# PRM_WKUP register map
Vendor: Texas Instruments
Peripheral module from a debugger description file (folder am335x).
Registers are 32-bit, access per field, no defined reset value unless marked. A register's access mark holds for its fields unless they carry their own. Offsets are as the file gives them; lines under a group give offsets from that group; [hi:lo] are bit positions; {n}, {i} and the like mark numbered series; 'fields as' and 'values as' point back to an identical list; <NAME> marks a mode.

## PRM_WKUP
0x00 RM_WKUP_RSTCTRL — This register controls the release of the ALWAYS ON Domain resets.
  [3] WKUP_M3_LRST rw — Assert Reset to WKUP_M3
    0=CLEAR (Reset is cleared for the M3); 1=ASSERT (Reset is asserted for the M3 by A8)
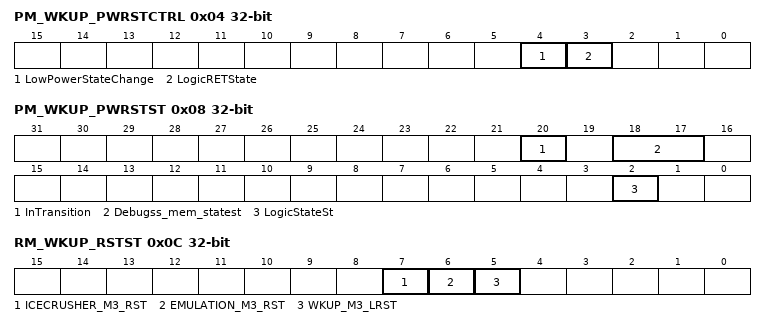
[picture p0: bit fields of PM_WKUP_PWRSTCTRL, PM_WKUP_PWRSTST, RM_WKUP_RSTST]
0x04 PM_WKUP_PWRSTCTRL — Controls power state of WKUP power domain
  [4] LowPowerStateChange rw — Power state change request when domain has already performed a sleep transition. Allows going into deeper low power state without waking up the power domain.
    0=DIS (Do not request a low power state change.); 1=EN (Request a low power state change. This bit is automatically cleared when the power state is effectively changed or when power state is ON.)
  [3] LogicRETState rw — Logic state when power domain is RETENTION
    0=logic_off (Only retention registers are retained and remaing logic is off when the domain is in RETENTION state.); 1=logic_ret (Whole logic is retained when domain is in RETENTION state.)
0x08 PM_WKUP_PWRSTST ro — This register provides a status on the current WKUP power domain state. [warm reset insensitive]
  [20] InTransition — Domain transition status
    0=No (No on-going transition on power domain); 1=Ongoing (Power domain transition is in progress.)
  [18:17] Debugss_mem_statest — WKUP domain memory state status
    0=Mem_off (Memory is OFF); 3=Mem_on (Memory is ON)
  [2] LogicStateSt — Logic state status
    0=OFF (Logic in domain is OFF); 1=ON (Logic in domain is ON)
0x0C RM_WKUP_RSTST — This register logs the different reset sources of the ALWON domain. Each bit is set upon release of the domain reset signal. Must be cleared by software. [warm reset insensitive]
  [all] fields
    0=RESET_NO (No reset); 1=RESET_YES (M3 Processor has been reset)
  [7] ICECRUSHER_M3_RST rw — M3 Processor has been reset due to M3 ICECRUSHER1 reset event
  [6] EMULATION_M3_RST rw — M3 Processor has been reset due to emulation reset source e.g. assert reset command initiated by the icepick module
  [5] WKUP_M3_LRST rw — M3 Processor has been reset
